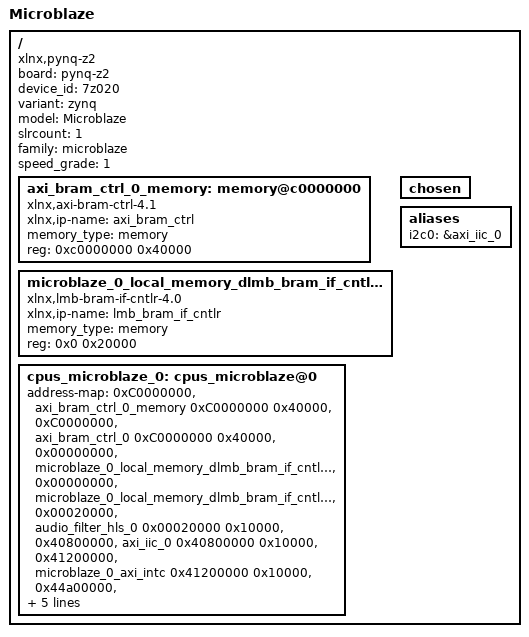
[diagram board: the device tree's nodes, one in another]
/dts-v1/;
#include "pl.dtsi"
/ {
	board = "pynq-z2";
	compatible = "xlnx,pynq-z2";
	device_id = "7z020";
	#address-cells = <1>;
	variant = "zynq";
	model = "Microblaze";
	#size-cells = <1>;
	slrcount = <1>;
	family = "microblaze";
	speed_grade = "1";
	axi_bram_ctrl_0_memory: memory@c0000000 {
		compatible = "xlnx,axi-bram-ctrl-4.1";
		xlnx,ip-name = "axi_bram_ctrl";
		device_type = "memory";
		memory_type = "memory";
		reg = <0xc0000000 0x40000>;
	};
	microblaze_0_local_memory_dlmb_bram_if_cntlr_memory: memory@0 {
		compatible = "xlnx,lmb-bram-if-cntlr-4.0";
		xlnx,ip-name = "lmb_bram_if_cntlr";
		device_type = "memory";
		memory_type = "memory";
		reg = <0x0 0x20000>;
	};
	chosen {
	};
	aliases {
		i2c0 = &axi_iic_0;
	};
	cpus_microblaze_0: cpus_microblaze@0 {
		address-map = <0xC0000000 &axi_bram_ctrl_0_memory 0xC0000000 0x40000>, 
			      <0xC0000000 &axi_bram_ctrl_0 0xC0000000 0x40000>, 
			      <0x00000000 &microblaze_0_local_memory_dlmb_bram_if_cntlr_memory 0x00000000 0x20000>, 
			      <0x00000000 &microblaze_0_local_memory_dlmb_bram_if_cntlr 0x00000000 0x20000>, 
			      <0x00020000 &audio_filter_hls_0 0x00020000 0x10000>, 
			      <0x40800000 &axi_iic_0 0x40800000 0x10000>, 
			      <0x41200000 &microblaze_0_axi_intc 0x41200000 0x10000>, 
			      <0x44a00000 &i2s_transmitter_0 0x44a00000 0x10000>, 
			      <0x44a10000 &audio_formatter_0 0x44a10000 0x10000>, 
			      <0x44a20000 &i2s_receiver_0 0x44a20000 0x10000>;
		#ranges-address-cells = <0x1>;
		#ranges-size-cells = <0x1>;
	};
};
